# STM32F303RDT6 register map
File version: 1.0
STM32F303RDT6,STM32F303RDT7,STM32F303RET6,STM32F303RET7,STM32F303VDH6,STM32F303VDT6,STM32F303VEH6,STM32F303VEH7,STM32F303VET6,STM32F303VET7,STM32F303VEY6,STM32F303VEY7,STM32F303ZDT6,STM32F303ZDT7,STM32F303ZET6,STM32F303ZET7,STM32F398VET6
Registers are 32-bit, access not given, reset 0x0 unless marked. A register's access mark holds for its fields unless they carry their own. Offsets are from the block's base; lines under a group give offsets from that group; [hi:lo] are bit positions; {n}, {i} and the like mark numbered series; 'fields as' and 'values as' point back to an identical list; <NAME> marks a mode.

## Memory map
0x40000000 TIM2
0x40000400 TIM3
0x40000800 TIM4
0x40001000 TIM6
0x40001400 TIM7
0x40002800 RTC
0x40002C00 WWDG
0x40003000 IWDG
0x40003800 SPI2
0x40003C00 SPI3
0x40004400 USART2
0x40004800 USART3
0x40004C00 UART4
0x40005000 UART5
0x40005400 I2C1
0x40005800 I2C2
0x40005C00 USBFS
0x40006000 USB
0x40006000 CANSRAM
0x40006400 CAN
0x40007000 PWR
0x40007400 DAC1
0x40007800 I2C3
0x40010000 SYSCFG
0x40010000 COMP
0x40010000 OPAMP
0x40010400 EXTI
0x40012C00 TIM1
0x40013000 SPI1
0x40013400 TIM8
0x40013800 USART1
0x40013C00 SPI4
0x40014000 TIM15
0x40014400 TIM16
0x40014800 TIM17
0x40015000 TIM20
0x40020000 DMA1
0x40020400 DMA2
0x40021000 RCC
0x40022000 FLASH
0x40023000 CRC
0x40024000 TSC
0x48000000 GPIOA
0x48000400 GPIOB
0x48000800 GPIOC
0x48000C00 GPIOD
0x48001000 GPIOE
0x48001400 GPIOF
0x48001800 GPIOG
0x48001C00 GPIOH
0x50000000 ADC1
0x50000100 ADC2
0x50000400 ADC3
0x50000500 ADC4
0x60000000 FMC12
0x80000400 FMC34
0xA0000400 FMC

## TIM2
Base 0x40000000
Same registers: TIM3 0x40000400, TIM4 0x40000800
0x00 CR1
  [11] UIFREMAP, [31:10] s, [9:8] CKD, [7] ARPE, [6:5] CMS, [4] DIR, [3] OPM, [2] URS, [1] UDIS, [0] CEN
0x04 CR2
  [7] TI1S, [6:4] MMS, [3] CCDS, [31:0] s
0x08 SMCR
  [31:17] s, [15] ETP, [14] ECE, [13:12] ETPS, [11:8] ETF, [7] MSM, [6:4] TS, [3] OCCS, [16:0] SMS
0x0C DIER
  [14] TDE, [13] COMDE, [n+8] CC{n}DE (n=1..4), [8] UDE, [6] TIE, [31:5] s, [n] CC{n}IE (n=1..4), [0] UIE
0x10 SR
  [n+8] CC{n}OF (n=1..4), [6] TIF, [31:5] s, [n] CC{n}IF (n=1..4), [0] UIF
0x14 EGR
  [6] TG, [31:5] s, [n] CC{n}G (n=1..4), [0] UG
0x18 CCMR1_OUT
  [31:17] s, [15] OC2CE, [24:12] OC2M, [11] OC2PE, [10] OC2FE, [9:8] CC2S, [7] OC1CE, [16:4] OC1M, [3] OC1PE, [2] OC1FE, [1:0] CC1S
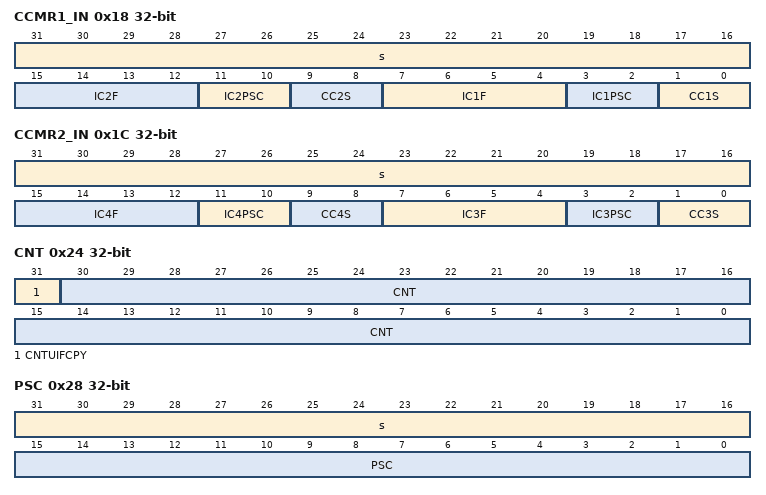
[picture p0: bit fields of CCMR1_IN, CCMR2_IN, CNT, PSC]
0x18 CCMR1_IN
  [31:16] s, [15:12] IC2F, [11:10] IC2PSC, [9:8] CC2S, [7:4] IC1F, [3:2] IC1PSC, [1:0] CC1S
0x1C CCMR2_OUT
  [31:17] s, [15] O24CE, [24:12] OC4M, [11] OC4PE, [10] OC4FE, [9:8] CC4S, [7] OC3CE, [16:4] OC3M, [3] OC3PE, [2] OC3FE, [1:0] CC3S
0x1C CCMR2_IN
  [31:16] s, [15:12] IC4F, [11:10] IC4PSC, [9:8] CC4S, [7:4] IC3F, [3:2] IC3PSC, [1:0] CC3S
0x20 CCER
  [4n-1] CC{n}NP (n=1..4), [4n-3] CC{n}P (n=1..4), [4n-4] CC{n}E (n=1..4), [31:2] s
0x24 CNT
  [31] CNTUIFCPY, [30:0] CNT
0x28 PSC
  [31:16] s, [15:0] PSC
0x2C ARR
{0x30+4i} CCR{i} (i=1..4)
0x48 DCR
  [12:8] DBL, [31:5] s, [4:0] DBA
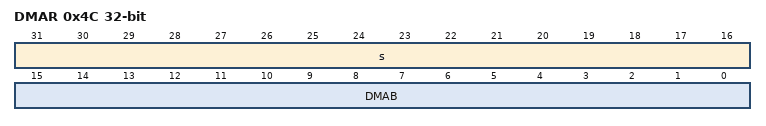
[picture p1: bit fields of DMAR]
0x4C DMAR
  [31:16] s, [15:0] DMAB

## TIM6
Base 0x40001000
Same registers: TIM7 0x40001400
0x00 CR1
  [11] UIFREMAP, [7] ARPE, [31:4] s, [3] OPM, [2] URS, [1] UDIS, [0] CEN
0x04 CR2
  [6:4] MMS, [31:0] s
0x0C DIER
  [8] UDE, [31:1] s, [0] UIE
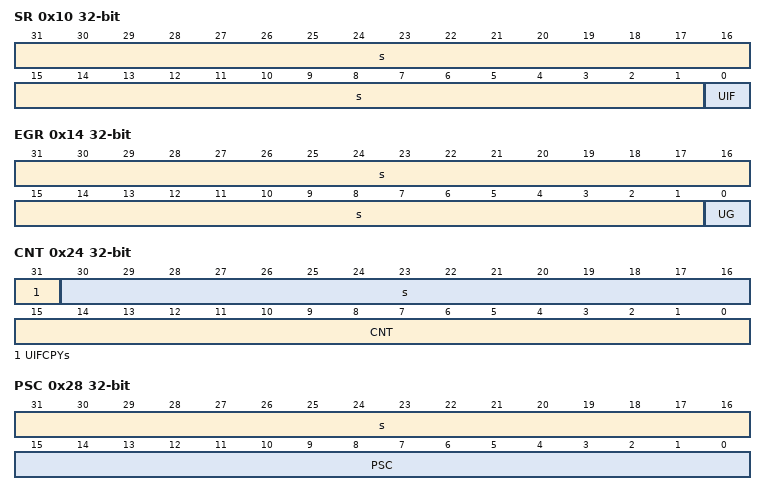
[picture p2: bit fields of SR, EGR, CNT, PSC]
0x10 SR
  [31:1] s, [0] UIF
0x14 EGR
  [31:1] s, [0] UG
0x24 CNT
  [31] UIFCPYs, [30:16] s, [15:0] CNT
0x28 PSC
  [31:16] s, [15:0] PSC
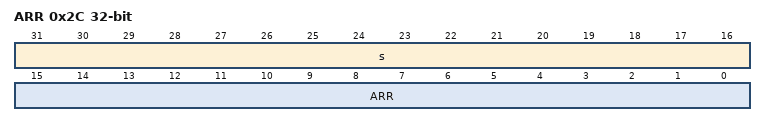
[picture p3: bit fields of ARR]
0x2C ARR
  [31:16] s, [15:0] ARR

## RTC
Base 0x40002800
0x00 TR
  [22] PM, [21:20] HT, [19:16] HU, [14:12] MNT, [11:8] MNU, [31:7] s, [6:4] ST, [3:0] SU
0x04 DR
  [23:20] YT, [19:16] YU, [15:13] WDU, [12] MT, [11:8] MU, [31:6] s, [5:4] DT, [3:0] DU
0x08 CR
  [23] COE, [22:21] OSEL, [20] POL, [19] COSEL, [18] BKP, [17] SUB1H, [16] ADD1H, [15] TSIE, [14] WUTIE, [13] ALRBIE, [12] ALRAIE, [11] TSE, [10] WUTE, [9] ALRBE, [8] ALRAE, [31:7] s, [6] FMT, [5] BYPSHAD, [4] REFCKON, [3] TSEDGE, [2:0] WUCKSEL
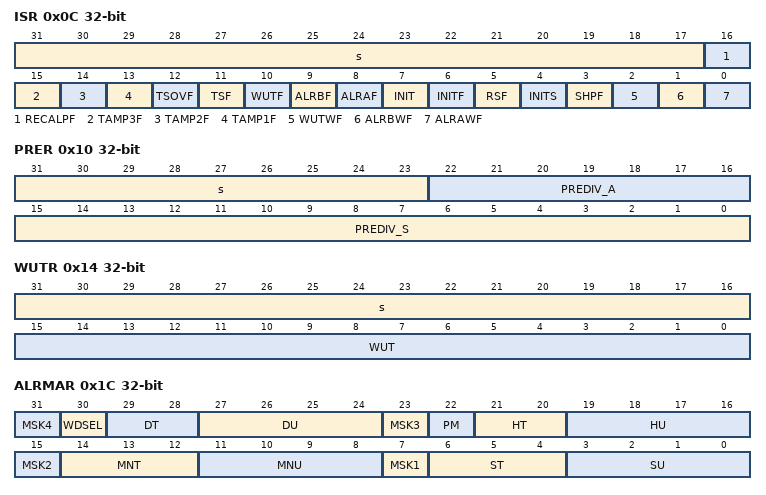
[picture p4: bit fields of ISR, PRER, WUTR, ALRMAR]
0x0C ISR
  [31:17] s, [16] RECALPF, [15] TAMP3F, [14] TAMP2F, [13] TAMP1F, [12] TSOVF, [11] TSF, [10] WUTF, [9] ALRBF, [8] ALRAF, [7] INIT, [6] INITF, [5] RSF, [4] INITS, [3] SHPF, [2] WUTWF, [1] ALRBWF, [0] ALRAWF
0x10 PRER
  [31:23] s, [22:16] PREDIV_A, [15:0] PREDIV_S
0x14 WUTR
  [31:16] s, [15:0] WUT
0x1C ALRMAR
  [8n-1] MSK{n} (n=1..4), [30] WDSEL, [29:28] DT, [27:24] DU, [22] PM, [21:20] HT, [19:16] HU, [14:12] MNT, [11:8] MNU, [6:4] ST, [3:0] SU
0x20 ALRMBR
  [31] MSK4, [30] WDSEL, [29:28] DT, [27:24] DU, [23] MSK3, [22] PM, [21:20] HT, [19:16] HU, [14:12] MNT, [11:8] MNU, [15:7] MSK2, [6:4] ST, [3:0] SU
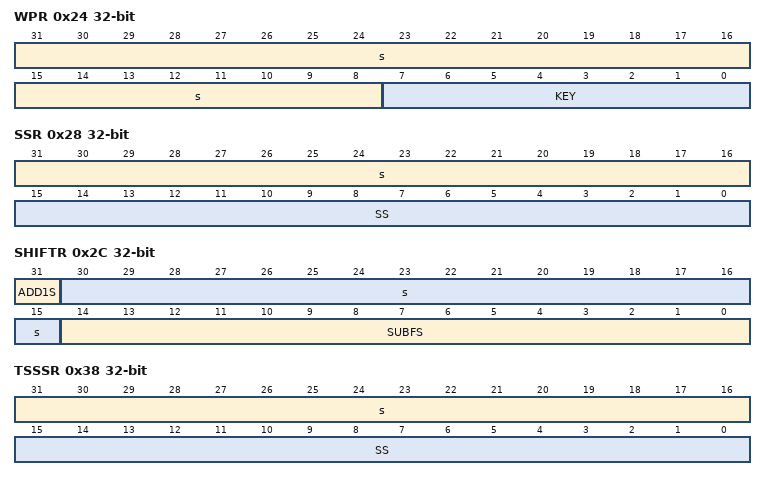
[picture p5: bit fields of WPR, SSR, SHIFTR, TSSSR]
0x24 WPR
  [31:8] s, [7:0] KEY
0x28 SSR
  [31:16] s, [15:0] SS
0x2C SHIFTR
  [31] ADD1S, [30:15] s, [14:0] SUBFS
0x30 TSTR
  fields as TR
0x34 TSDR
  [15:13] WDU, [12] MT, [11:8] MU, [31:6] s, [5:4] DT, [3:0] DU
0x38 TSSSR
  [31:16] s, [15:0] SS
0x3C CALR
  [15] CALP, [14] CALW8, [13] CALW16, [31:9] s, [8:0] CALM
0x40 TAFCR
  [23:22] PC15MODE, [21] PC14VALUE, [20] PC14MODE, [19:18] PC13VALUE, [31:16] s, [15] TAMPPUDIS, [14:13] TAMPPRCH, [12:11] TAMPFLT, [10:8] TAMPFREQ, [7] TAMPTS, [6] TAMP3TRG, [5] TAMP3E, [4] TAMP2TRG, [3] TAMP2E, [2] TAMPIE, [1] TAMP1TRG, [0] TAMP1E
0x44 ALRMASSR
  [27:24] MASKSS, [31:15] s, [14:0] SS
0x48 ALRMBSSR
  [27:24] MASKSS, [31:15] s, [14:0] SS
{0x50+4i} BKP{i}R (i=0..15)
  [31:0] BKP
